VERSION "HSCAN6"

NS_ :

BS_:

BU_: Merged DBC

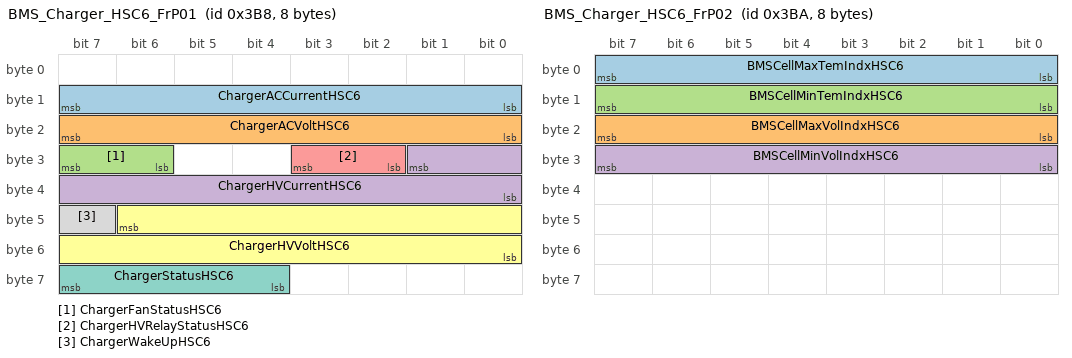
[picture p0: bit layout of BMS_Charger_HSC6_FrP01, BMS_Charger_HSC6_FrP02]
BO_ 952 BMS_Charger_HSC6_FrP01: 8 BMS
 SG_ ChargerACCurrentHSC6 : 15|8@0+ (0.2,0) [0|50.8] "A"  vector__xxx
 SG_ ChargerACVoltHSC6 : 23|8@0+ (2,0) [0|508] "V"  vector__xxx
 SG_ ChargerFanStatusHSC6 : 31|2@0+ (1,0) [0|3] ""  vector__xxx
 SG_ ChargerHVCurrentHSC6 : 25|10@0+ (0.02,0) [0|20.44] "A"  vector__xxx
 SG_ ChargerHVRelayStatusHSC6 : 27|2@0+ (1,0) [0|3] ""  vector__xxx
 SG_ ChargerHVVoltHSC6 : 46|15@0+ (0.02,0) [0|655.32] "V"  vector__xxx
 SG_ ChargerStatusHSC6 : 63|4@0+ (1,0) [0|15] ""  Telematics_BOX
 SG_ ChargerWakeUpHSC6 : 47|1@0+ (1,0) [0|1] ""  vector__xxx

BO_ 954 BMS_Charger_HSC6_FrP02: 8 BMS
 SG_ BMSCellMaxTemIndxHSC6 : 7|8@0+ (1,0) [0|254] ""  Telematics_BOX
 SG_ BMSCellMaxVolIndxHSC6 : 23|8@0+ (1,0) [0|254] ""  Telematics_BOX
 SG_ BMSCellMinTemIndxHSC6 : 15|8@0+ (1,0) [0|254] ""  Telematics_BOX
 SG_ BMSCellMinVolIndxHSC6 : 31|8@0+ (1,0) [0|254] ""  Telematics_BOX

BO_ 956 BMS_Charger_HSC6_FrP03: 8 BMS
 SG_ ChargerLVCurrentHSC6 : 55|8@0+ (0.1,0) [0|25.4] "A"  vector__xxx
 SG_ ChargerLVVoltHSC6 : 63|8@0+ (0.1,0) [0|25.4] "V"  vector__xxx

BO_ 958 BMS_Charger_HSC6_FrP04: 8 BMS
 SG_ BMSCellTemHSC6 : 15|8@0+ (1,-40) [-40|215] "¡æ"  Telematics_BOX
 SG_ BMSCellTemIndxHSC6 : 39|8@0+ (1,0) [0|254] ""  Telematics_BOX
 SG_ BMSCellTemVHSC6 : 7|1@0+ (1,0) [0|1] ""  Telematics_BOX
 SG_ BMSCellVolHSC6 : 19|12@0+ (0.001,1) [1|5.095] "V"  Telematics_BOX
 SG_ BMSCellVolIndxHSC6 : 47|8@0+ (1,0) [0|254] ""  Telematics_BOX
 SG_ BMSCellVolVHSC6 : 6|1@0+ (1,0) [0|1] ""  Telematics_BOX
 SG_ BMSOnBodChrgCmdHSC6 : 53|3@0+ (1,0) [0|7] ""  Tester
 SG_ ChargerInletTempOTPHSC6 : 1|1@0+ (1,0) [0|1] ""  Tester
 SG_ ChargerInsideTemp1OTPHSC6 : 0|1@0+ (1,0) [0|1] ""  Tester
 SG_ ChrgrAltCrntLmtHSC6 : 31|8@0- (0.5,0) [-64|63.5] "A"  Tester
 SG_ ChrgrHVILClsdHSC6 : 63|1@0+ (1,0) [0|1] ""  Tester
 SG_ OBCCPPWMDutyHSC6 : 62|7@0+ (1,0) [0|100] ""  Tester
 SG_ OBCCPPWMStaHSC6 : 50|3@0+ (1,0) [0|7] ""  Tester

BO_ 659 BMS_HSC6_FrP00: 8 BMS
 SG_ BMSBalancingDoneHSC6 : 18|1@0+ (1,0) [0|1] ""  Tester
 SG_ BMSBalancingStatusHSC6 : 24|1@0+ (1,0) [0|1] ""  Telematics_BOX,Tester
 SG_ BMSCellBalancingCountHSC6 : 15|8@0+ (1,0) [0|253] ""  Tester
 SG_ BMSCellOverVoltHSC6 : 39|1@0+ (1,0) [0|1] ""  Tester
 SG_ BMSCellUnderVoltHSC6 : 19|1@0+ (1,0) [0|1] ""  Tester
 SG_ BMSContactorPowerCmdHSC6 : 16|1@0+ (1,0) [0|1] ""  Tester
 SG_ BMSContactorPowerMonHSC6 : 25|1@0+ (1,0) [0|1] ""  Tester
 SG_ BMSCrashCircuitStatusHSC6 : 17|1@0+ (1,0) [0|1] ""  Tester
 SG_ BMSEEpromWipHSC6 : 38|1@0+ (1,0) [0|1] ""  Tester
 SG_ BMSLVBatInputHSC6 : 7|8@0+ (0.1,0) [0|25.3] "V"  Telematics_BOX,Tester
 SG_ BMSModuleEnableHSC6 : 27|1@0+ (1,0) [0|1] ""  Tester
 SG_ BMSNegRelayStatusHSC6 : 47|2@0+ (1,0) [0|3] ""  Telematics_BOX,Tester
 SG_ BMSOffbdChargerWakeupHSC6 : 30|1@0+ (1,0) [0|1] ""  Tester
 SG_ BMSOnbdChargerWakeupHSC6 : 28|1@0+ (1,0) [0|1] ""  Tester
 SG_ BMSPosRelayStatusHSC6 : 33|2@0+ (1,0) [0|3] ""  Telematics_BOX,Tester
 SG_ BMSPreRelayStatusHSC6 : 35|2@0+ (1,0) [0|3] ""  Telematics_BOX,Tester
 SG_ BMSPTIsolationLevelHSC6 : 37|2@0+ (1,0) [0|3] ""  Tester
 SG_ BMSReadyHSC6 : 26|1@0+ (1,0) [0|1] ""  Tester
 SG_ BMSRelayStepHSC6 : 23|4@0+ (1,0) [0|15] ""  Telematics_BOX,Tester
 SG_ BMSVehicleWakeupHSC6 : 29|1@0+ (1,0) [0|1] ""  Telematics_BOX,Tester
 SG_ BMSBusbarMaxTempHSC6 : 55|8@0+ (0.5,-40) [-40|86.5] "℃"  Tester

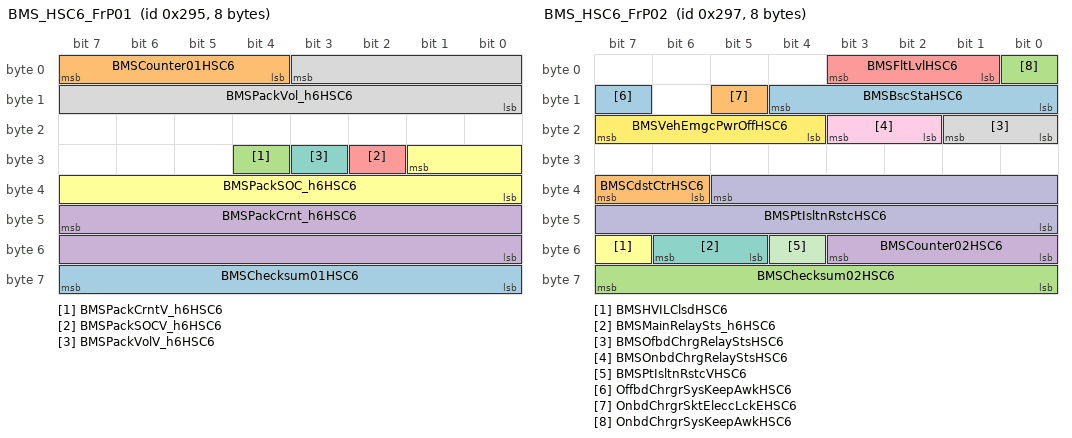
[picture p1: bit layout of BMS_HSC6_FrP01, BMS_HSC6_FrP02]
BO_ 661 BMS_HSC6_FrP01: 8 BMS
 SG_ BMSChecksum01HSC6 : 63|8@0+ (1,0) [0|0] ""  HCU
 SG_ BMSCounter01HSC6 : 7|4@0+ (1,0) [0|15] "count value"  HCU
 SG_ BMSPackCrntV_h6HSC6 : 28|1@0+ (1,0) [0|1] ""  Telematics_BOX,HCU,TC
 SG_ BMSPackCrnt_h6HSC6 : 47|16@0+ (0.025,-1000) [-1000|638.375] "A"  Telematics_BOX,HCU,TC
 SG_ BMSPackSOCV_h6HSC6 : 26|1@0+ (1,0) [0|1] ""  Telematics_BOX,HCU,TC
 SG_ BMSPackSOC_h6HSC6 : 25|10@0+ (0.1,0) [0|102.3] "%"  Telematics_BOX,HCU,TC
 SG_ BMSPackVolV_h6HSC6 : 27|1@0+ (1,0) [0|1] ""  Telematics_BOX,HCU,TC
 SG_ BMSPackVol_h6HSC6 : 3|12@0+ (0.25,0) [0|1023.75] "V"  Telematics_BOX,HCU,TC

BO_ 663 BMS_HSC6_FrP02: 8 BMS
 SG_ BMSBscStaHSC6 : 12|5@0+ (1,0) [0|31] ""  Telematics_BOX,HCU,TC
 SG_ BMSCdstCtrHSC6 : 39|2@0+ (1,0) [0|3] ""  Telematics_BOX,HCU
 SG_ BMSChecksum02HSC6 : 63|8@0+ (1,0) [0|0] ""  HCU
 SG_ BMSCounter02HSC6 : 51|4@0+ (1,0) [0|15] "count value"  HCU,TC
 SG_ BMSFltLvlHSC6 : 3|3@0+ (1,0) [0|7] ""  Telematics_BOX,HCU
 SG_ BMSHVILClsdHSC6 : 55|1@0+ (1,0) [0|1] ""  Telematics_BOX,HCU
 SG_ BMSMainRelaySts_h6HSC6 : 54|2@0+ (1,0) [0|3] ""  Telematics_BOX,HCU,TC
 SG_ BMSOfbdChrgRelayStsHSC6 : 17|2@0+ (1,0) [0|3] ""  vector__xxx
 SG_ BMSOnbdChrgRelayStsHSC6 : 19|2@0+ (1,0) [0|3] ""  vector__xxx
 SG_ BMSPtIsltnRstcHSC6 : 37|14@0+ (0.5,0) [0|8191.5] "kOhm"  Telematics_BOX,HCU
 SG_ BMSPtIsltnRstcVHSC6 : 52|1@0+ (1,0) [0|1] ""  Telematics_BOX,HCU
 SG_ BMSVehEmgcPwrOffHSC6 : 23|4@0+ (1,0) [0|15] ""  Tester
 SG_ OffbdChrgrSysKeepAwkHSC6 : 15|1@0+ (1,0) [0|1] ""  Telematics_BOX,HCU
 SG_ OnbdChrgrSktEleccLckEHSC6 : 13|1@0+ (1,0) [0|1] ""  HCU
 SG_ OnbdChrgrSysKeepAwkHSC6 : 0|1@0+ (1,0) [0|1] ""  Telematics_BOX,HCU

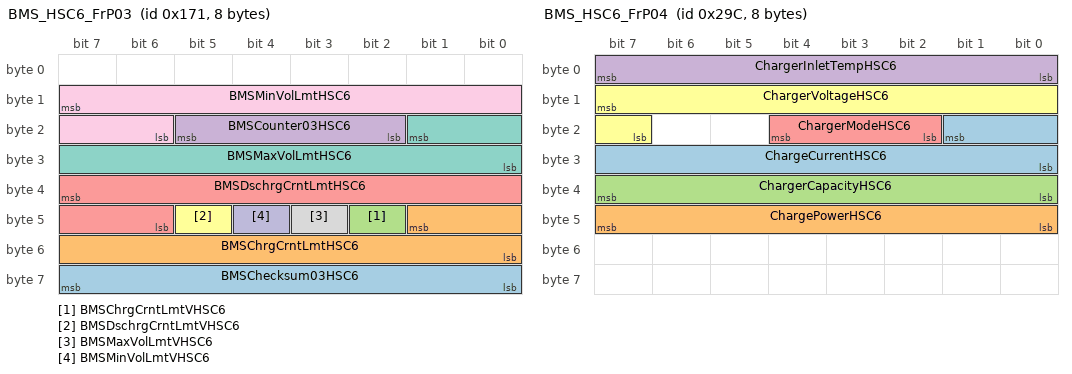
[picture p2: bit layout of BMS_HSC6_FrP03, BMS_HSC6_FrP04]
BO_ 369 BMS_HSC6_FrP03: 8 BMS
 SG_ BMSChecksum03HSC6 : 63|8@0+ (1,0) [0|0] ""  TC
 SG_ BMSChrgCrntLmtHSC6 : 41|10@0+ (1,-1023) [-1023|0] "A"  HCU,TC
 SG_ BMSChrgCrntLmtVHSC6 : 42|1@0+ (1,0) [0|1] ""  HCU,TC
 SG_ BMSCounter03HSC6 : 21|4@0+ (1,0) [0|15] "count value"  TC
 SG_ BMSDschrgCrntLmtHSC6 : 39|10@0+ (1,0) [0|1023] "A"  HCU,TC
 SG_ BMSDschrgCrntLmtVHSC6 : 45|1@0+ (1,0) [0|1] ""  HCU,TC
 SG_ BMSMaxVolLmtHSC6 : 17|10@0+ (1,0) [0|1023] "V"  TC
 SG_ BMSMaxVolLmtVHSC6 : 43|1@0+ (1,0) [0|1] ""  TC
 SG_ BMSMinVolLmtHSC6 : 15|10@0+ (1,0) [0|1023] "V"  TC
 SG_ BMSMinVolLmtVHSC6 : 44|1@0+ (1,0) [0|1] ""  TC

BO_ 668 BMS_HSC6_FrP04: 8 BMS
 SG_ ChargeCurrentHSC6 : 17|10@0+ (0.02,0) [0|20.44] "fail"  vector__xxx
 SG_ ChargePowerHSC6 : 47|8@0+ (0.05,0) [0|12.7] "kw"  vector__xxx
 SG_ ChargerCapacityHSC6 : 39|8@0+ (1,0) [0|254] "Ah"  vector__xxx
 SG_ ChargerInletTempHSC6 : 7|8@0+ (1,-40) [-40|215] "DegC"  vector__xxx
 SG_ ChargerModeHSC6 : 20|3@0+ (1,0) [0|7] ""  vector__xxx
 SG_ ChargerVoltageHSC6 : 15|9@0+ (1,0) [0|430] ""  Tester

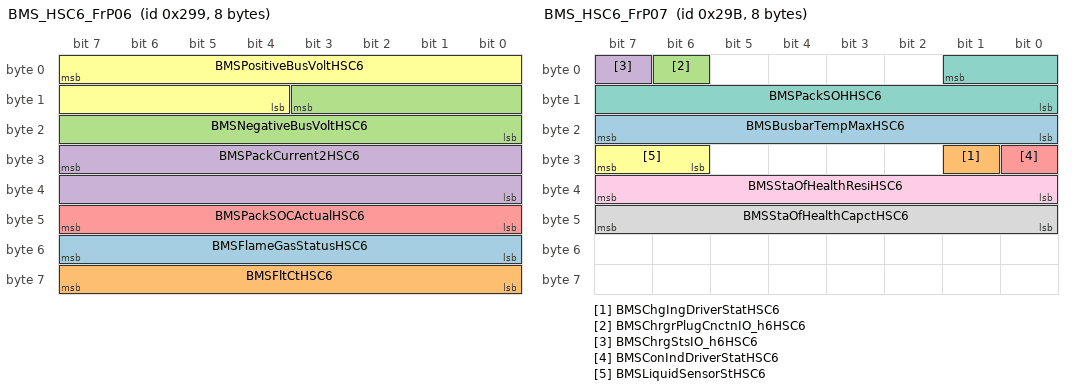
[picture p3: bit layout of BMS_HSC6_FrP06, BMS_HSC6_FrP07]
BO_ 665 BMS_HSC6_FrP06: 8 BMS
 SG_ BMSFlameGasStatusHSC6 : 55|8@0+ (0.5,0) [0|126.5] "%"  Tester
 SG_ BMSFltCtHSC6 : 63|8@0+ (1,0) [0|255] ""  Tester
 SG_ BMSNegativeBusVoltHSC6 : 11|12@0+ (0.25,-500) [-500|523.25] "V"  Tester
 SG_ BMSPackCurrent2HSC6 : 31|16@0+ (0.025,-1000) [-1000|638.325] "A"  Tester
 SG_ BMSPackSOCActualHSC6 : 47|8@0+ (0.5,0) [0|126.5] "%"  Tester
 SG_ BMSPositiveBusVoltHSC6 : 7|12@0+ (0.25,0) [0|1023.25] "V"  Tester

BO_ 667 BMS_HSC6_FrP07: 8 BMS
 SG_ BMSBusbarTempMaxHSC6 : 23|8@0+ (0.5,-40) [-40|86.5] "DegC"  Tester
 SG_ BMSChgIngDriverStatHSC6 : 25|1@0+ (1,0) [0|1] ""  vector__xxx
 SG_ BMSChrgrPlugCnctnIO_h6HSC6 : 6|1@0+ (1,0) [0|1] ""  Telematics_BOX
 SG_ BMSChrgStsIO_h6HSC6 : 7|1@0+ (1,0) [0|1] ""  Telematics_BOX
 SG_ BMSConIndDriverStatHSC6 : 24|1@0+ (1,0) [0|1] ""  Tester
 SG_ BMSLiquidSensorStHSC6 : 31|2@0+ (1,0) [0|3] ""  Tester
 SG_ BMSPackSOHHSC6 : 1|10@0+ (0.1,0) [0|102.1] "%"  Tester
 SG_ BMSStaOfHealthCapctHSC6 : 47|8@0+ (0.5,0) [0|126.5] "%"  Tester
 SG_ BMSStaOfHealthResiHSC6 : 39|8@0+ (0.5,0) [0|126.5] "%"  Tester

BO_ 1100 BMS_HSC6_FrP08: 1 BMS
 SG_ keep_network_BMSHSC6 : 0|1@0+ (1,0) [0|1] ""  Telematics_BOX
 SG_ keep_network_BMSHSC6_UB : 1|1@0+ (1,0) [0|1] ""  Telematics_BOX

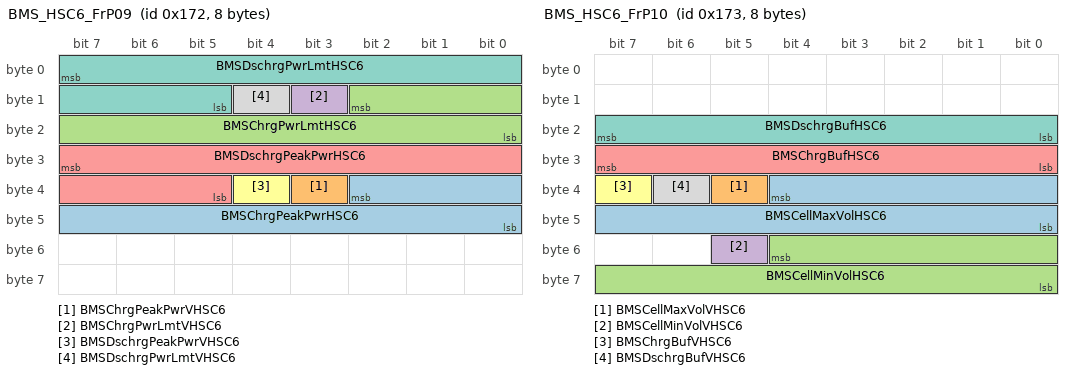
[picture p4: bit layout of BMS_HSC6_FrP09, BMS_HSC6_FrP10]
BO_ 370 BMS_HSC6_FrP09: 8 BMS
 SG_ BMSChrgPeakPwrHSC6 : 34|11@0+ (0.1,0) [0|204.7] "kw"  HCU
 SG_ BMSChrgPeakPwrVHSC6 : 35|1@0+ (1,0) [0|1] ""  HCU
 SG_ BMSChrgPwrLmtHSC6 : 10|11@0+ (0.1,0) [0|204.7] "kw"  HCU
 SG_ BMSChrgPwrLmtVHSC6 : 11|1@0+ (1,0) [0|1] ""  HCU
 SG_ BMSDschrgPeakPwrHSC6 : 31|11@0+ (0.1,0) [0|204.7] "kw"  HCU
 SG_ BMSDschrgPeakPwrVHSC6 : 36|1@0+ (1,0) [0|1] ""  HCU
 SG_ BMSDschrgPwrLmtHSC6 : 7|11@0+ (0.1,0) [0|204.7] "kw"  HCU
 SG_ BMSDschrgPwrLmtVHSC6 : 12|1@0+ (1,0) [0|1] ""  HCU

BO_ 371 BMS_HSC6_FrP10: 8 BMS
 SG_ BMSCellMaxVolHSC6 : 36|13@0+ (0.001,0) [0|8.191] "V"  Telematics_BOX
 SG_ BMSCellMaxVolVHSC6 : 37|1@0+ (1,0) [0|1] ""  Telematics_BOX,Tester
 SG_ BMSCellMinVolHSC6 : 52|13@0+ (0.001,0) [0|8.191] "V"  Telematics_BOX
 SG_ BMSCellMinVolVHSC6 : 53|1@0+ (1,0) [0|1] ""  Telematics_BOX,Tester
 SG_ BMSChrgBufHSC6 : 31|8@0+ (0.5,0) [0|127.5] "%"  HCU
 SG_ BMSChrgBufVHSC6 : 39|1@0+ (1,0) [0|1] ""  HCU
 SG_ BMSDschrgBufHSC6 : 23|8@0+ (0.5,0) [0|127.5] "%"  HCU
 SG_ BMSDschrgBufVHSC6 : 38|1@0+ (1,0) [0|1] ""  HCU

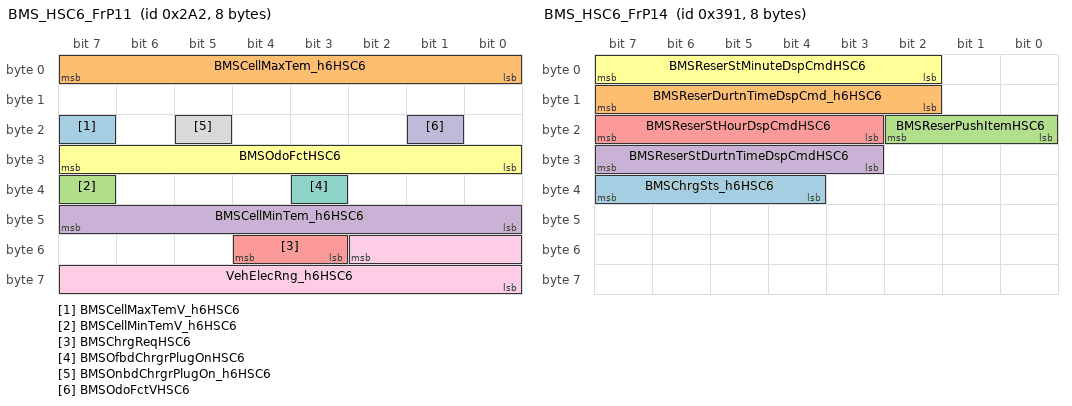
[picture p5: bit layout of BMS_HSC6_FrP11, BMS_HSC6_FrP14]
BO_ 674 BMS_HSC6_FrP11: 8 BMS
 SG_ BMSCellMaxTemV_h6HSC6 : 23|1@0+ (1,0) [0|1] ""  Telematics_BOX,Tester
 SG_ BMSCellMaxTem_h6HSC6 : 7|8@0+ (0.5,-40) [-40|87.5] "DegC"  Telematics_BOX,Tester
 SG_ BMSCellMinTemV_h6HSC6 : 39|1@0+ (1,0) [0|1] ""  Telematics_BOX,Tester
 SG_ BMSCellMinTem_h6HSC6 : 47|8@0+ (0.5,-40) [-40|87.5] "Deg C"  Telematics_BOX,Tester
 SG_ BMSChrgReqHSC6 : 52|2@0+ (1,0) [0|3] ""  HCU
 SG_ BMSOdoFctHSC6 : 31|8@0+ (0.5,0) [0|127.5] "%"  Tester
 SG_ BMSOfbdChrgrPlugOnHSC6 : 35|1@0+ (1,0) [0|1] ""  HCU
 SG_ BMSOnbdChrgrPlugOn_h6HSC6 : 21|1@0+ (1,0) [0|1] ""  Telematics_BOX
 SG_ VehElecRng_h6HSC6 : 50|11@0+ (1,0) [0|2047] "km"  Telematics_BOX
 SG_ BMSOdoFctVHSC6 : 17|1@0+ (1,0) [0|1] ""  Tester

BO_ 939 BMS_HSC6_FrP12: 8 BMS
 SG_ BMSAvlblEnrg_h6HSC6 : 47|8@0+ (0.1,0) [0|25.5] "kWh"  Telematics_BOX
 SG_ HVBatElecEnrgAvgRate_h6HSC6 : 25|10@0+ (0.1,-20) [-20|82.3] ""  Telematics_BOX

BO_ 940 BMS_HSC6_FrP13: 8 BMS
 SG_ BMSPackSOCDsp_h6HSC6 : 17|10@0+ (0.1,0) [0|102.3] ""  Telematics_BOX

BO_ 913 BMS_HSC6_FrP14: 8 BMS
 SG_ BMSChrgSts_h6HSC6 : 39|4@0+ (1,0) [0|15] ""  Telematics_BOX
 SG_ BMSReserDurtnTimeDspCmd_h6HSC6 : 15|6@0+ (0.5,0) [0|20] ""  Telematics_BOX
 SG_ BMSReserPushItemHSC6 : 18|3@0+ (1,0) [0|7] ""  Telematics_BOX
 SG_ BMSReserStDurtnTimeDspCmdHSC6 : 31|5@0+ (1,0) [0|23] ""  Telematics_BOX
 SG_ BMSReserStHourDspCmdHSC6 : 23|5@0+ (1,0) [0|31] ""  Telematics_BOX
 SG_ BMSReserStMinuteDspCmdHSC6 : 7|6@0+ (1,0) [0|63] ""  Telematics_BOX

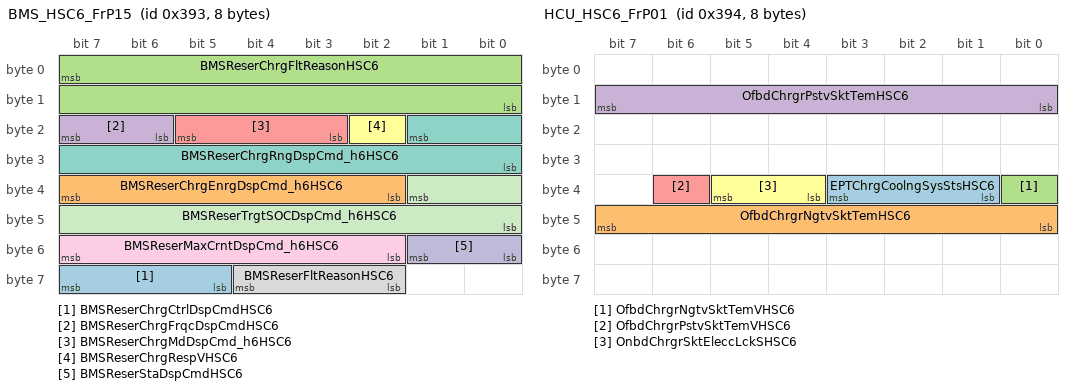
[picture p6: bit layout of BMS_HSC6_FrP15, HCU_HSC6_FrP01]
BO_ 915 BMS_HSC6_FrP15: 8 BMS
 SG_ BMSReserChrgCtrlDspCmdHSC6 : 63|3@0+ (1,0) [0|7] ""  Telematics_BOX
 SG_ BMSReserChrgEnrgDspCmd_h6HSC6 : 39|6@0+ (1,0) [0|63] ""  Telematics_BOX
 SG_ BMSReserChrgFltReasonHSC6 : 7|16@0+ (1,0) [0|65535] ""  Telematics_BOX
 SG_ BMSReserChrgFrqcDspCmdHSC6 : 23|2@0+ (1,0) [0|3] ""  Telematics_BOX
 SG_ BMSReserChrgMdDspCmd_h6HSC6 : 21|3@0+ (1,0) [0|7] ""  Telematics_BOX
 SG_ BMSReserChrgRespVHSC6 : 18|1@0+ (1,0) [0|1] ""  Telematics_BOX
 SG_ BMSReserChrgRngDspCmd_h6HSC6 : 17|10@0+ (1,0) [0|1023] ""  Telematics_BOX
 SG_ BMSReserFltReasonHSC6 : 60|3@0+ (1,0) [0|7] ""  Telematics_BOX
 SG_ BMSReserMaxCrntDspCmd_h6HSC6 : 55|6@0+ (1,0) [0|32] ""  Telematics_BOX
 SG_ BMSReserStaDspCmdHSC6 : 49|2@0+ (1,0) [0|3] ""  Telematics_BOX
 SG_ BMSReserTrgtSOCDspCmd_h6HSC6 : 33|10@0+ (0.1,0) [0|102.3] ""  Telematics_BOX

BO_ 936 BMS_HSC6_FrP16: 8 BMS
 SG_ ChrgngRmnngTimeV_h6HSC6 : 54|1@0+ (1,0) [0|1] ""  Telematics_BOX
 SG_ ChrgngRmnngTime_h6HSC6 : 31|10@0+ (1,0) [0|1023] "minute"  Telematics_BOX

BO_ 1091 BMS_HSC6_FrS00: 1 BMS
 SG_ wake_network_BMSHSC6 : 0|1@0+ (1,0) [0|1] ""  Telematics_BOX
 SG_ wake_network_BMSHSC6_UB : 1|1@0+ (1,0) [0|1] ""  Telematics_BOX

BO_ 916 HCU_HSC6_FrP01: 8 HCU
 SG_ EPTChrgCoolngSysStsHSC6 : 35|3@0+ (1,0) [0|7] ""  BMS
 SG_ OfbdChrgrNgtvSktTemHSC6 : 47|8@0+ (1,-40) [-40|215] "¡æ"  BMS
 SG_ OfbdChrgrNgtvSktTemVHSC6 : 32|1@0+ (1,0) [0|1] ""  BMS
 SG_ OfbdChrgrPstvSktTemHSC6 : 15|8@0+ (1,-40) [-40|215] "¡æ"  BMS
 SG_ OfbdChrgrPstvSktTemVHSC6 : 38|1@0+ (1,0) [0|1] ""  BMS
 SG_ OnbdChrgrSktEleccLckSHSC6 : 37|2@0+ (1,0) [0|3] ""  BMS

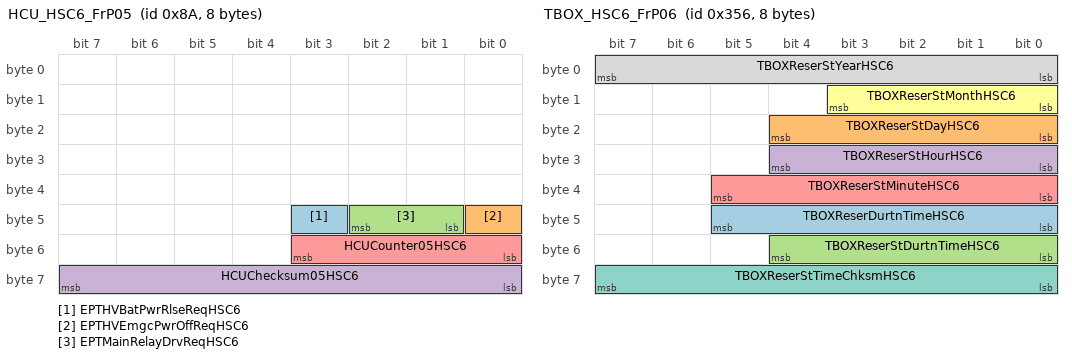
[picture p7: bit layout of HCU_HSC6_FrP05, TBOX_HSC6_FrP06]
BO_ 138 HCU_HSC6_FrP05: 8 HCU
 SG_ EPTHVBatPwrRlseReqHSC6 : 43|1@0+ (1,0) [0|1] ""  BMS
 SG_ EPTHVEmgcPwrOffReqHSC6 : 40|1@0+ (1,0) [0|1] ""  BMS
 SG_ EPTMainRelayDrvReqHSC6 : 42|2@0+ (1,0) [0|3] ""  BMS
 SG_ HCUChecksum05HSC6 : 63|8@0+ (1,0) [0|255] ""  BMS
 SG_ HCUCounter05HSC6 : 51|4@0+ (1,0) [0|15] ""  BMS

BO_ 854 TBOX_HSC6_FrP06: 8 Telematics_BOX
 SG_ TBOXReserDurtnTimeHSC6 : 45|6@0+ (0.5,0) [0|20] ""  BMS
 SG_ TBOXReserStDayHSC6 : 20|5@0+ (1,0) [0|31] ""  BMS
 SG_ TBOXReserStDurtnTimeHSC6 : 52|5@0+ (1,0) [0|23] ""  BMS
 SG_ TBOXReserStHourHSC6 : 28|5@0+ (1,0) [0|31] ""  BMS
 SG_ TBOXReserStMinuteHSC6 : 37|6@0+ (1,0) [0|63] ""  BMS
 SG_ TBOXReserStMonthHSC6 : 11|4@0+ (1,0) [0|15] ""  BMS
 SG_ TBOXReserStTimeChksmHSC6 : 63|8@0+ (1,0) [0|255] ""  BMS
 SG_ TBOXReserStYearHSC6 : 7|8@0+ (1,2000) [2000|2255] ""  BMS

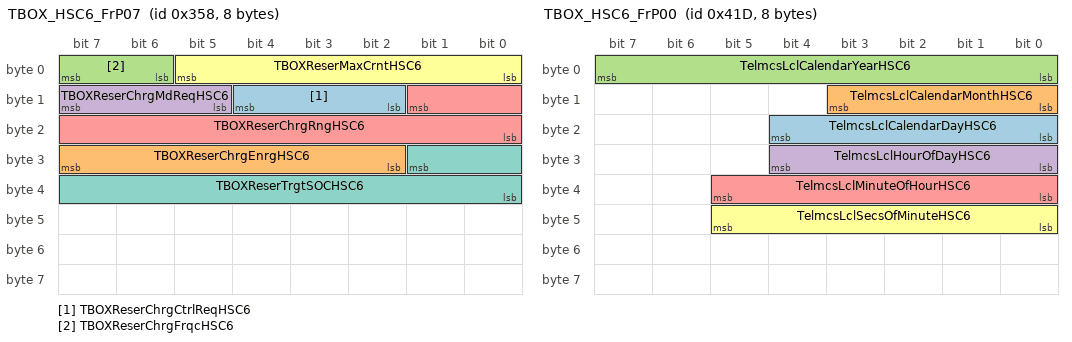
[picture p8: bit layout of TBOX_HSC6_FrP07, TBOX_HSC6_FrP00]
BO_ 856 TBOX_HSC6_FrP07: 8 Telematics_BOX
 SG_ TBOXReserChrgCtrlReqHSC6 : 12|3@0+ (1,0) [0|7] ""  BMS
 SG_ TBOXReserChrgEnrgHSC6 : 31|6@0+ (1,0) [0|63] ""  BMS
 SG_ TBOXReserChrgFrqcHSC6 : 7|2@0+ (1,0) [0|3] ""  BMS
 SG_ TBOXReserChrgMdReqHSC6 : 15|3@0+ (1,0) [0|7] ""  BMS
 SG_ TBOXReserChrgRngHSC6 : 9|10@0+ (1,0) [0|1023] ""  BMS
 SG_ TBOXReserMaxCrntHSC6 : 5|6@0+ (1,0) [0|32] ""  BMS
 SG_ TBOXReserTrgtSOCHSC6 : 25|10@0+ (0.1,0) [0|102.3] ""  BMS

BO_ 1055 TBOX_HSC6_NWM: 3 Telematics_BOX
 SG_ network_mode_h6 : 23|8@0+ (1,0) [0|255] ""  BMS
 SG_ signal_config_id_h6 : 7|16@0+ (1,0) [0|65535] ""  BMS

BO_ 153 TC_HSC6_FrP02: 8 TC
 SG_ TMInvtrCrntHSC6 : 23|11@0+ (1,-1024) [-1024|1023] "A"  BMS
 SG_ TMInvtrCrntVHSC6 : 28|1@0+ (1,0) [0|1] ""  BMS

BO_ 331 TC_HSC6_FrP08: 8 TC
 SG_ TMInvtrVolHSC6 : 1|10@0+ (1,0) [0|1021] ""  BMS
 SG_ TMInvtrVolVHSC6 : 2|1@0+ (1,0) [0|1] ""  BMS

BO_ 150 ISC_HSC6_FrP04: 8 ISC
 SG_ ISGInvtrCrntHSC6 : 7|11@0+ (1,-1024) [-1024|1023] "A"  BMS
 SG_ ISGInvtrCrntVHSC6 : 12|1@0+ (1,0) [0|1] ""  BMS

BO_ 917 ISC_HSC6_FrP07: 8 ISC
 SG_ ISGInvtrVolHSC6 : 49|10@0+ (1,0) [0|1021] "V"  BMS
 SG_ ISGInvtrVolVHSC6 : 50|1@0+ (1,0) [0|1] ""  BMS

BO_ 1053 TBOX_HSC6_FrP00: 8 TBOX
 SG_ TelmcsLclCalendarDayHSC6 : 20|5@0+ (1,0) [0|31] ""  BMS
 SG_ TelmcsLclCalendarMonthHSC6 : 11|4@0+ (1,0) [0|15] ""  BMS
 SG_ TelmcsLclCalendarYearHSC6 : 7|8@0+ (1,2000) [2000|2255] ""  BMS
 SG_ TelmcsLclHourOfDayHSC6 : 28|5@0+ (1,0) [0|23] ""  BMS
 SG_ TelmcsLclMinuteOfHourHSC6 : 37|6@0+ (1,0) [0|59] ""  BMS
 SG_ TelmcsLclSecsOfMinuteHSC6 : 45|6@0+ (1,0) [0|59] ""  BMS

BO_ 1051 TBOX_HSC6_FrP03: 8 TBOX
 SG_ TBOXUnvslTimeChksmHSC6 : 63|8@0+ (1,0) [0|255] ""  BMS

BA_DEF_  "BaudRate" FLOAT 1000 1000000;
BA_DEF_ BO_  "GenMsgSendType" ENUM  "cyclic","Spontaneous","cyclicIfActive","spontaneousWithDelay","Immediate";
BA_DEF_ BO_  "GenMsgCycleTime" FLOAT 0 300000;
BA_DEF_ BO_  "GenMsgDelayTime" FLOAT 0 300000;
BA_DEF_ SG_  "GenSigStartValue" INT -9.22337203685478E+018 1.84467440737096E+019;
BA_DEF_DEF_  "BaudRate" 1000;
BA_DEF_DEF_  "GenMsgSendType" "";
BA_DEF_DEF_  "GenMsgCycleTime" 0;
BA_DEF_DEF_  "GenMsgDelayTime" 0;
BA_DEF_DEF_  "GenSigStartValue" 0;
BA_ "BaudRate" 500000;
BA_DEF_ SG_  "GenSigPubLatency" INT 0 200;
BA_DEF_ SG_  "GenSigWriteInterval" INT 0 5000;
BA_DEF_DEF_  "GenSigPubLatency" 0;
BA_DEF_DEF_  "GenSigWriteInterval" 0;
BA_ "GenMsgSendType" BO_ 952 0;
BA_ "GenMsgCycleTime" BO_ 952 100;
BA_ "GenMsgSendType" BO_ 954 0;
BA_ "GenMsgCycleTime" BO_ 954 100;
BA_ "GenMsgSendType" BO_ 956 0;
BA_ "GenMsgCycleTime" BO_ 956 100;
BA_ "GenMsgSendType" BO_ 958 0;
BA_ "GenMsgCycleTime" BO_ 958 100;
BA_ "GenMsgSendType" BO_ 659 0;
BA_ "GenMsgCycleTime" BO_ 659 50;
BA_ "GenMsgSendType" BO_ 661 0;
BA_ "GenMsgCycleTime" BO_ 661 20;
BA_ "GenMsgSendType" BO_ 663 0;
BA_ "GenMsgCycleTime" BO_ 663 50;
BA_ "GenMsgSendType" BO_ 369 0;
BA_ "GenMsgCycleTime" BO_ 369 20;
BA_ "GenMsgSendType" BO_ 668 0;
BA_ "GenMsgCycleTime" BO_ 668 100;
BA_ "GenMsgSendType" BO_ 665 0;
BA_ "GenMsgCycleTime" BO_ 665 50;
BA_ "GenMsgSendType" BO_ 667 0;
BA_ "GenMsgCycleTime" BO_ 667 50;
BA_ "GenMsgSendType" BO_ 1100 0;
BA_ "GenMsgCycleTime" BO_ 1100 100;
BA_ "GenMsgSendType" BO_ 370 0;
BA_ "GenMsgCycleTime" BO_ 370 20;
BA_ "GenMsgSendType" BO_ 371 0;
BA_ "GenMsgCycleTime" BO_ 371 20;
BA_ "GenMsgSendType" BO_ 674 0;
BA_ "GenMsgCycleTime" BO_ 674 100;
BA_ "GenMsgSendType" BO_ 939 0;
BA_ "GenMsgCycleTime" BO_ 939 100;
BA_ "GenMsgSendType" BO_ 940 0;
BA_ "GenMsgCycleTime" BO_ 940 100;
BA_ "GenMsgSendType" BO_ 913 0;
BA_ "GenMsgCycleTime" BO_ 913 100;
BA_ "GenMsgSendType" BO_ 915 0;
BA_ "GenMsgCycleTime" BO_ 915 100;
BA_ "GenMsgSendType" BO_ 936 0;
BA_ "GenMsgCycleTime" BO_ 936 100;
BA_ "GenMsgSendType" BO_ 1091 1;
BA_ "GenMsgSendType" BO_ 916 0;
BA_ "GenMsgCycleTime" BO_ 916 100;
BA_ "GenMsgSendType" BO_ 138 0;
BA_ "GenMsgCycleTime" BO_ 138 10;
BA_ "GenMsgSendType" BO_ 854 0;
BA_ "GenMsgCycleTime" BO_ 854 100;
BA_ "GenMsgSendType" BO_ 856 0;
BA_ "GenMsgCycleTime" BO_ 856 100;
BA_ "GenMsgSendType" BO_ 1055 4;
BA_ "GenMsgSendType" BO_ 153 0;
BA_ "GenMsgCycleTime" BO_ 153 10;
BA_ "GenMsgSendType" BO_ 331 0;
BA_ "GenMsgCycleTime" BO_ 331 10;
BA_ "GenMsgSendType" BO_ 150 0;
BA_ "GenMsgCycleTime" BO_ 150 10;
BA_ "GenMsgSendType" BO_ 917 0;
BA_ "GenMsgCycleTime" BO_ 917 100;
BA_ "GenMsgSendType" BO_ 1053 0;
BA_ "GenMsgCycleTime" BO_ 1053 200;
BA_ "GenMsgSendType" BO_ 1051 0;
BA_ "GenMsgCycleTime" BO_ 1051 200;
BA_ "GenSigPubLatency" SG_ 1100 keep_network_BMSHSC6 10;
BA_ "GenSigWriteInterval" SG_ 1100 keep_network_BMSHSC6 10;
BA_ "GenSigPubLatency" SG_ 1091 wake_network_BMSHSC6 10;
BA_ "GenSigWriteInterval" SG_ 1091 wake_network_BMSHSC6 10;
VAL_ 1100 keep_network_BMSHSC6 1 "keep network request" 0 "no keep network request" ;
VAL_ 1091 wake_network_BMSHSC6 1 "wake-up network request" 0 "no wake-up network request" ;
